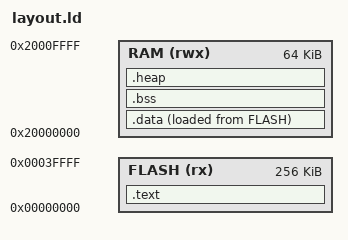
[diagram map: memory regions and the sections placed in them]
ENTRY(Reset_Handler)

MEMORY
{
    FLASH (rx)  : ORIGIN = 0x00000000, LENGTH = 256K
    RAM   (rwx) : ORIGIN = 0x20000000, LENGTH = 64K
}

SECTIONS
{
    .text :
    {
        KEEP(*(.vectors))
        *(.text*)
        *(.rodata*)
    } > FLASH

    .data :
    {
        *(.data*)
    } > RAM AT > FLASH

    .bss :
    {
        __bss_start__ = .;
        *(.bss*)
        *(COMMON)
        __bss_end__ = .;
    } > RAM

    .heap :
    {
        __end__ = .;
        end = .;
        *(.heap*)
    } > RAM

    __stack = ORIGIN(RAM) + LENGTH(RAM);
}
